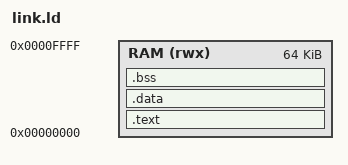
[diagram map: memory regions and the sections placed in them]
ENTRY(_start)

MEMORY
{
  RAM (rwx) : ORIGIN = 0x00000000, LENGTH = 64K
}

SECTIONS
{
  .text : {
    *(.text.start)
    *(.text*)
    *(.rodata*)
  } > RAM

  .data : {
    *(.data*)
  } > RAM

  .bss (NOLOAD) : {
    *(.bss*)
    *(COMMON)
  } > RAM

  __stack = ORIGIN(RAM) + LENGTH(RAM) - 4;
}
